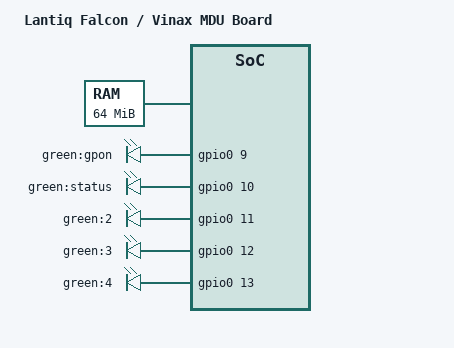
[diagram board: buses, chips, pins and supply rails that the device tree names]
#include "falcon.dtsi"
#include "falcon_sflash-16m.dtsi"

#include <dt-bindings/gpio/gpio.h>

/ {
	model = "Lantiq Falcon / Vinax MDU Board";
	compatible = "lantiq,falcon-mdu", "lantiq,falcon";

	aliases {
		spi0 = &ebu_cs0;
	};

	memory@0 {
		device_type = "memory";
		reg = <0x0 0x4000000>;  // 64M at 0x0
	};

	leds {
		compatible = "gpio-leds";
		pinctrl-names = "default";
		pinctrl-0 = <&bootled_pins>;

		LED_0 {
			label = "green:gpon";
			gpios = <&gpio0 9 GPIO_ACTIVE_HIGH>;
			default-state = "keep";
		};
		LED_1 {
			label = "green:status";
			gpios = <&gpio0 10 GPIO_ACTIVE_HIGH>;
			default-state = "keep";
		};
		LED_2 {
			label = "green:2";
			gpios = <&gpio0 11 GPIO_ACTIVE_HIGH>;
			default-state = "keep";
		};
		LED_3 {
			label = "green:3";
			gpios = <&gpio0 12 GPIO_ACTIVE_HIGH>;
			default-state = "keep";
		};
		LED_4 {
			label = "green:4";
			gpios = <&gpio0 13 GPIO_ACTIVE_HIGH>;
			default-state = "keep";
		};
	};
};

